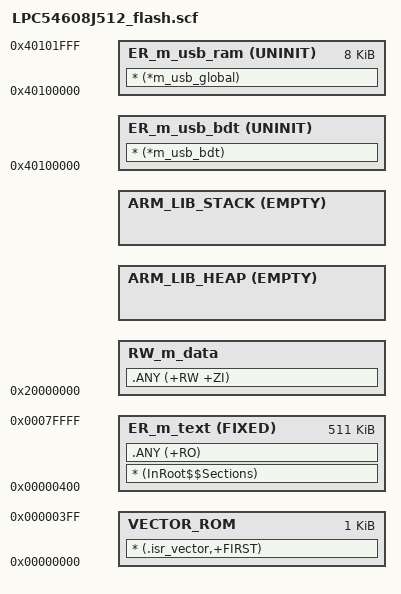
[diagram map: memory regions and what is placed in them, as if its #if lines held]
#!armclang --target=arm-arm-none-eabi -mcpu=cortex-m4 -E -x c 
;#! armcc -E调用预处理器
/*
** ###################################################################
**     Processors:          LPC54608J512BD208
**                          LPC54608J512ET180
**
**     Compiler:            Keil ARM C/C++ Compiler
**     Reference manual:    LPC546xx User manual Rev.1.9  5 June 2017
**     Version:             rev. 1.2, 2017-06-08
**     Build:               b190923
**
**     Abstract:
**         Linker file for the Keil ARM C/C++ Compiler
**
**     Copyright 2016 Freescale Semiconductor, Inc.
**     Copyright 2016-2019 NXP
**     All rights reserved.
**
**     SPDX-License-Identifier: BSD-3-Clause
**
**     http:                 www.nxp.com
**     mail:                 support@nxp.com
**
** ###################################################################
*/
;调用预处理器就是说可以在分散加载中使用一些预处理器语句 比如#define
#define m_interrupts_start             0x00000000
#define m_interrupts_size              0x00000400

#define m_text_start                   0x00000400
#define m_text_size                    0x0007FC00

#define m_data_start                   0x20000000
#define m_data_size                    0x00028000

#define m_usb_sram_start               0x40100000
#define m_usb_sram_size                0x00002000

/* USB BDT size */
#define usb_bdt_size                   0x0
/* Sizes */
#if (defined(__stack_size__))
  #define Stack_Size                   __stack_size__
#else
  #define Stack_Size                   0x0400
#endif

#if (defined(__heap_size__))
  #define Heap_Size                    __heap_size__
#else
  #define Heap_Size                    0x0400
#endif
;         0x00000000         0x00000400  + 0x0007FC00  - 0x00000000
LR_m_text m_interrupts_start m_text_start+m_text_size-m_interrupts_start { ; load region size_region
;             0x00000000         0x00000400
  VECTOR_ROM m_interrupts_start m_interrupts_size { ; load address = execution address
    ;*.o (RESET, +First) 异常&中断向量表，+First表示强制放到首地址
	* (.isr_vector,+FIRST)
  }
;           0x00000400         0x0007FC00
  ER_m_text m_text_start FIXED m_text_size { ; load address = execution address
    * (InRoot$$Sections)	;ARM相关库，InRoot$$Sections就是ARM库节的链接器标号
    .ANY (+RO)
  }
;            0x20000000  0x00028000    0x0400    0x0400
  RW_m_data m_data_start m_data_size-Stack_Size-Heap_Size { ; RW data
    .ANY (+RW +ZI)			;SRAM上的RW、ZI数据段
  }
  ARM_LIB_HEAP +0 EMPTY Heap_Size {    ; Heap region growing up
  }
  ARM_LIB_STACK m_data_start+m_data_size EMPTY -Stack_Size { ; Stack region growing down
  }
}

LR_m_usb_bdt m_usb_sram_start usb_bdt_size {
  ER_m_usb_bdt m_usb_sram_start UNINIT usb_bdt_size {
    * (*m_usb_bdt)
  }
}

LR_m_usb_ram (m_usb_sram_start + usb_bdt_size) (m_usb_sram_size - usb_bdt_size) {
  ER_m_usb_ram (m_usb_sram_start + usb_bdt_size) UNINIT (m_usb_sram_size - usb_bdt_size) {
    * (*m_usb_global)
  }
}

;LR_IROM2 0x10000000 0x00001000  {
;  ER_IROM2 0x10000000 0x00001000 {
;    freertos.o(i.GPIO_Init)
;}
;}

;LR_IROM1 0x00000000 0x00080000  {
;  ER_IROM1 0x00000000 0x00080000  {
;   *.o (RESET)
;   *(InRoot$$Sections)
;   .ANY (+RO)
;  }
;  RW_IRAM1 0x20000000 0x00010000  {
;   .ANY (+RW +ZI)
;  }
;}
